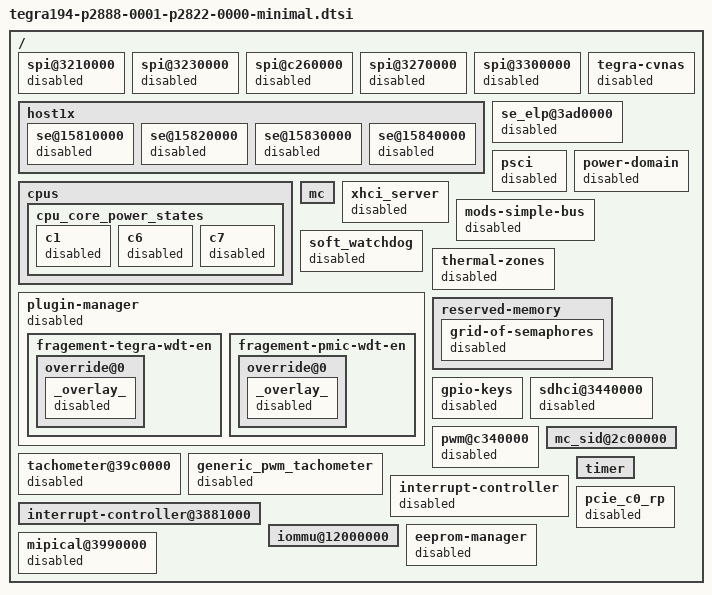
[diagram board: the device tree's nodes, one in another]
/*
 * This override include file disables all the nodes that are not required for
 * boot to console. The nodes that are disabled here are for CVM:P2888-0001 and
 * CVB:P28222-0000 platforms.
 *
 * Copyright (c) 2017, NVIDIA CORPORATION.  All rights reserved.
 *
 * This program is free software; you can redistribute it and/or modify
 * it under the terms of the GNU General Public License as published by
 * the Free Software Foundation; version 2 of the License.
 *
 * This program is distributed in the hope that it will be useful, but WITHOUT
 * ANY WARRANTY; without even the implied warranty of MERCHANTABILITY or
 * FITNESS FOR A PARTICULAR PURPOSE.  See the GNU General Public License for
 * more details.
 */

/ {

	spi@3210000 {
		status = "disabled";
	};

	spi@3230000 {
		status = "disabled";
	};

	spi@c260000 {
		status = "disabled";
	};

	spi@3270000 {
		status = "disabled";
	};

	spi@3300000 {
		status = "disabled";
	};

	host1x {
		se@15810000 {
			status = "disabled";
		};

		se@15820000 {
			status = "disabled";
		};

		se@15830000 {
			status = "disabled";
		};

		se@15840000 {
			status = "disabled";
		};

	};

	cpus {
		cpu_core_power_states {

			c1 {
				status = "disabled";
			};

			c6 {
				status = "disabled";
			};

			c7 {
				status = "disabled";
			};
		};
	};

	tegra-cvnas {
		status = "disabled";
	};

	se_elp@3ad0000 {
		status = "disabled";
	};

	psci {
		status = "disabled";
	};

	power-domain {
		status = "disabled";
	};

	mc {
		status = "okay";
	};

	xhci_server {
		status = "disabled";
	};

	mods-simple-bus {
		status = "disabled";
	};

	soft_watchdog {
		status = "disabled";
	};

	plugin-manager {
		status = "disabled";
	};

	thermal-zones {
		status = "disabled";
	};

	reserved-memory {
		grid-of-semaphores {
			status = "disabled";
		};
	};

	plugin-manager {
		status = "disabled";

		fragement-tegra-wdt-en {

			override@0 {

				_overlay_ {
					status = "disabled";
				};
			};
		};

		fragement-pmic-wdt-en {

			override@0 {

				_overlay_ {
					status = "disabled";
				};
			};
		};
	};

	gpio-keys {
		status = "disabled";
	};

	sdhci@3440000 {
		status = "disabled";
	};

	pwm@c340000 {
		status = "disabled";
	};

	mc_sid@2c00000 {
		status = "okay";
	};

	tachometer@39c0000 {
		status = "disabled";
	};

	generic_pwm_tachometer {
		status = "disabled";
	};

	interrupt-controller {
		status = "disabled";
	};

	interrupt-controller@3881000 {
		status = "okay";
	};

	timer {
		status="okay";
	};

	iommu@12000000 {
		status = "okay";
	};

	eeprom-manager {
		status = "disabled";
	};

	pcie_c0_rp {
		status = "disabled";
	};

	mipical@3990000 {
		status = "disabled";
	};
};
